# mc200 register map
Registers are 32-bit, access not given, no defined reset value unless marked. A register's access mark holds for its fields unless they carry their own. Addresses are absolute; registers are grouped by the start of their names; [hi:lo] are bit positions; {n}, {i} and the like mark numbered series; 'fields as' and 'values as' point back to an identical list.

## ACOMP
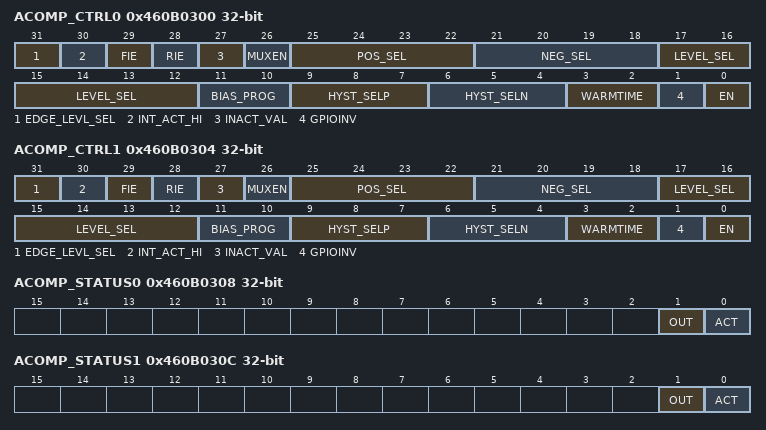
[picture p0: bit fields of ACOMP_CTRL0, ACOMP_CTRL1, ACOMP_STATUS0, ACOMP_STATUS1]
0x460B0300 ACOMP_CTRL0
  [31] EDGE_LEVL_SEL, [30] INT_ACT_HI, [29] FIE, [28] RIE, [27] INACT_VAL, [26] MUXEN, [25:22] POS_SEL, [21:18] NEG_SEL, [17:12] LEVEL_SEL, [11:10] BIAS_PROG, [9:7] HYST_SELP, [6:4] HYST_SELN, [3:2] WARMTIME, [1] GPIOINV, [0] EN
0x460B0304 ACOMP_CTRL1
  fields as ACOMP_CTRL0
0x460B0308 ACOMP_STATUS0
  [1] OUT, [0] ACT
0x460B030C ACOMP_STATUS1
  [1] OUT, [0] ACT
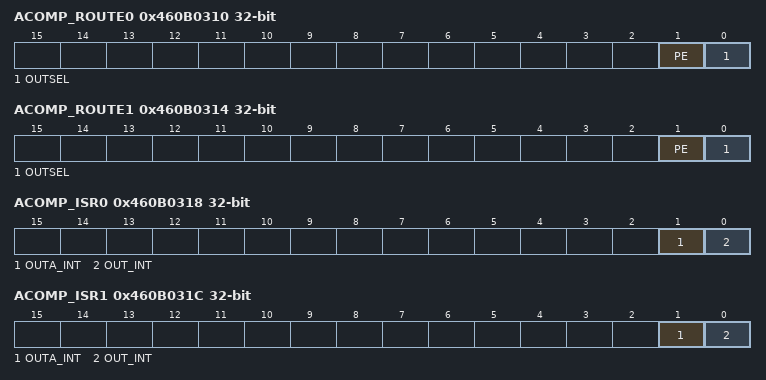
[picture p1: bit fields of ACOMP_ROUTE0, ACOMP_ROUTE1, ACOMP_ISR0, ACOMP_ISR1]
0x460B0310 ACOMP_ROUTE0
  [1] PE, [0] OUTSEL
0x460B0314 ACOMP_ROUTE1
  [1] PE, [0] OUTSEL
0x460B0318 ACOMP_ISR0
  [1] OUTA_INT, [0] OUT_INT
0x460B031C ACOMP_ISR1
  [1] OUTA_INT, [0] OUT_INT
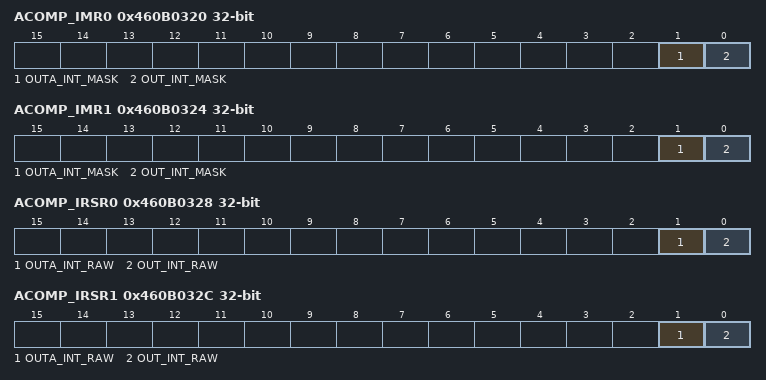
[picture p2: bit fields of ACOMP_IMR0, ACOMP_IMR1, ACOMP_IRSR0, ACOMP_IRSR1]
0x460B0320 ACOMP_IMR0
  [1] OUTA_INT_MASK, [0] OUT_INT_MASK
0x460B0324 ACOMP_IMR1
  [1] OUTA_INT_MASK, [0] OUT_INT_MASK
0x460B0328 ACOMP_IRSR0
  [1] OUTA_INT_RAW, [0] OUT_INT_RAW
0x460B032C ACOMP_IRSR1
  [1] OUTA_INT_RAW, [0] OUT_INT_RAW
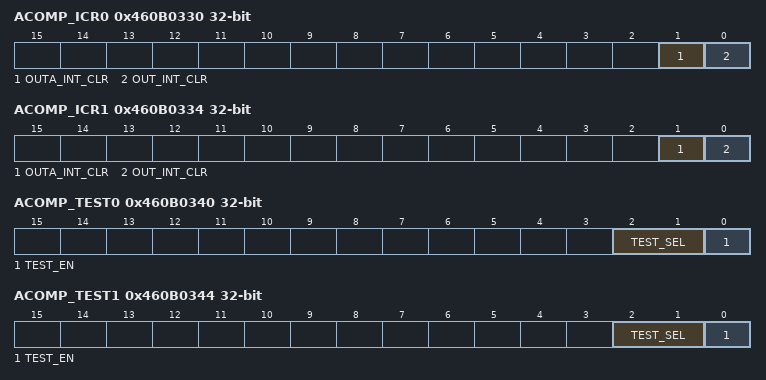
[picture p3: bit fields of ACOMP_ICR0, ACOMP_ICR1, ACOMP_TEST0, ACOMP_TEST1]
0x460B0330 ACOMP_ICR0
  [1] OUTA_INT_CLR, [0] OUT_INT_CLR
0x460B0334 ACOMP_ICR1
  [1] OUTA_INT_CLR, [0] OUT_INT_CLR
0x460B0338 ACOMP_RST0
  [0] SOFT_RST
0x460B033C ACOMP_RST1
  [0] SOFT_RST
0x460B0340 ACOMP_TEST0
  [2:1] TEST_SEL, [0] TEST_EN
0x460B0344 ACOMP_TEST1
  [2:1] TEST_SEL, [0] TEST_EN
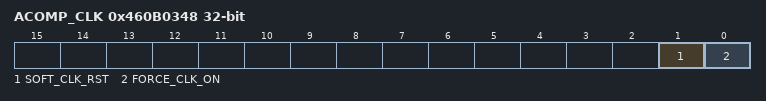
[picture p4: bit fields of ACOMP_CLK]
0x460B0348 ACOMP_CLK
  [1] SOFT_CLK_RST, [0] FORCE_CLK_ON
0x460B034C ACOMP_RSVD

## BG
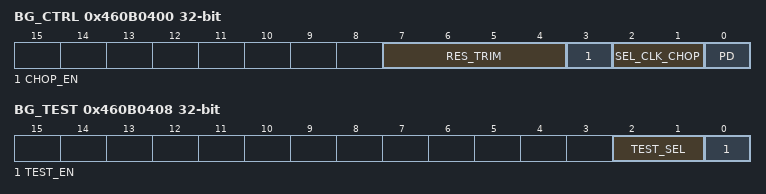
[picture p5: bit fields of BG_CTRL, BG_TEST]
0x460B0400 BG_CTRL
  [7:4] RES_TRIM, [3] CHOP_EN, [2:1] SEL_CLK_CHOP, [0] PD
0x460B0404 BG_STATUS
  [0] RDY
0x460B0408 BG_TEST
  [2:1] TEST_SEL, [0] TEST_EN
0x460B040C BG_RSVD

## CAUDBG
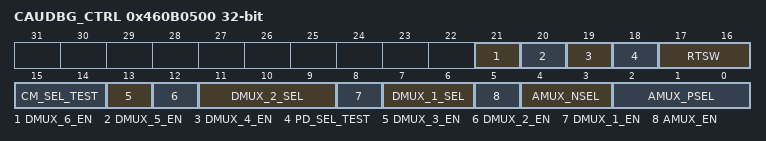
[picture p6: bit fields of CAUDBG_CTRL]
0x460B0500 CAUDBG_CTRL
  [21] DMUX_6_EN, [20] DMUX_5_EN, [19] DMUX_4_EN, [18] PD_SEL_TEST, [17:16] RTSW, [15:14] CM_SEL_TEST, [13] DMUX_3_EN, [12] DMUX_2_EN, [11:9] DMUX_2_SEL, [8] DMUX_1_EN, [7:6] DMUX_1_SEL, [5] AMUX_EN, [4:3] AMUX_NSEL, [2:0] AMUX_PSEL
0x460B0504 CAUDBG_RSVD

## SSP2
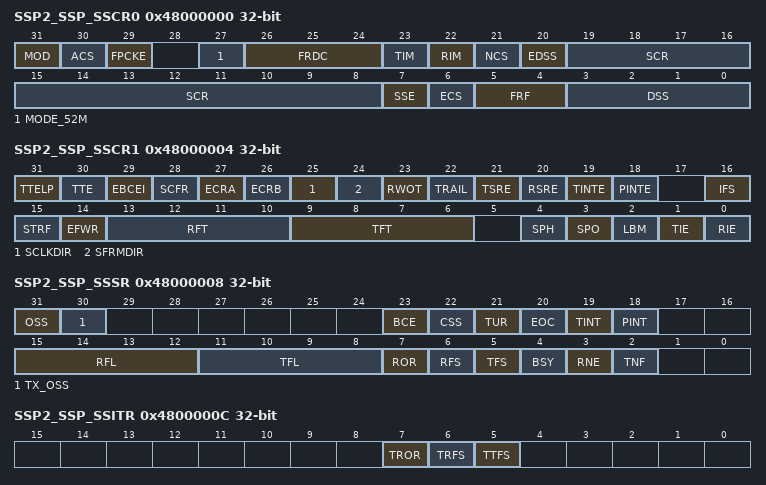
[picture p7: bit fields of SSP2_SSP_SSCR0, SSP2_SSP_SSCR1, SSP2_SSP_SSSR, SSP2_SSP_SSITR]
0x48000000 SSP2_SSP_SSCR0
  [31] MOD, [30] ACS, [29] FPCKE, [27] MODE_52M, [26:24] FRDC, [23] TIM, [22] RIM, [21] NCS, [20] EDSS, [19:8] SCR, [7] SSE, [6] ECS, [5:4] FRF, [3:0] DSS
0x48000004 SSP2_SSP_SSCR1
  [31] TTELP, [30] TTE, [29] EBCEI, [28] SCFR, [27] ECRA, [26] ECRB, [25] SCLKDIR, [24] SFRMDIR, [23] RWOT, [22] TRAIL, [21] TSRE, [20] RSRE, [19] TINTE, [18] PINTE, [16] IFS, [15] STRF, [14] EFWR, [13:10] RFT, [9:6] TFT, [4] SPH, [3] SPO, [2] LBM, [1] TIE, [0] RIE
0x48000008 SSP2_SSP_SSSR
  [31] OSS, [30] TX_OSS, [23] BCE, [22] CSS, [21] TUR, [20] EOC, [19] TINT, [18] PINT, [15:12] RFL, [11:8] TFL, [7] ROR, [6] RFS, [5] TFS, [4] BSY, [3] RNE, [2] TNF
0x4800000C SSP2_SSP_SSITR
  [7] TROR, [6] TRFS, [5] TTFS
0x48000010 SSP2_SSP_SSDR
  [31:0] DATA
0x48000028 SSP2_SSP_SSTO
  [23:0] TIMEOUT
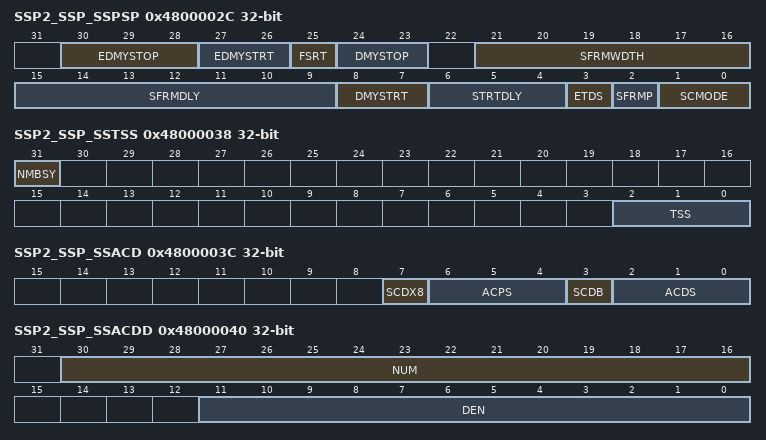
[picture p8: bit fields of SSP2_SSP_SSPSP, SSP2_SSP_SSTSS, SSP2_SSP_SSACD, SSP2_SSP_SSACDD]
0x4800002C SSP2_SSP_SSPSP
  [30:28] EDMYSTOP, [27:26] EDMYSTRT, [25] FSRT, [24:23] DMYSTOP, [21:16] SFRMWDTH, [15:9] SFRMDLY, [8:7] DMYSTRT, [6:4] STRTDLY, [3] ETDS, [2] SFRMP, [1:0] SCMODE
0x48000030 SSP2_SSP_SSTSA
  [7:0] TTSA
0x48000034 SSP2_SSP_SSRSA
  [7:0] RTSA
0x48000038 SSP2_SSP_SSTSS
  [31] NMBSY, [2:0] TSS
0x4800003C SSP2_SSP_SSACD
  [7] SCDX8, [6:4] ACPS, [3] SCDB, [2:0] ACDS
0x48000040 SSP2_SSP_SSACDD
  [30:16] NUM, [11:0] DEN

## PIN
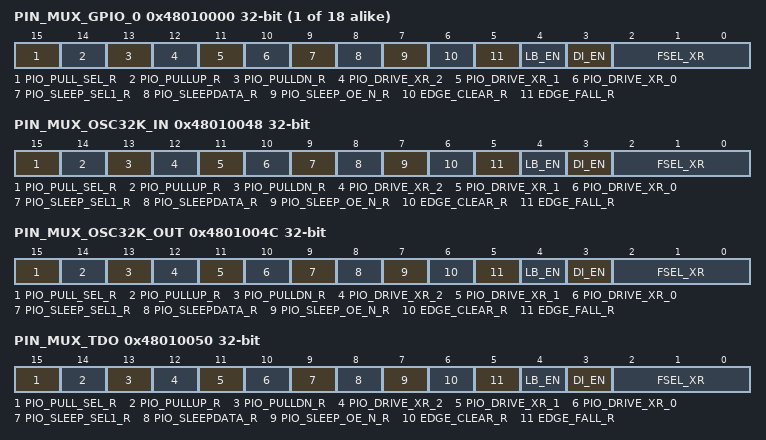
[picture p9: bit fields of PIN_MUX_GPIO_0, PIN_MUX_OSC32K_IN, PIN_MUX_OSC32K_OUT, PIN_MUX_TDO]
{0x48010000+4i} PIN_MUX_GPIO_{i} (i=0..17)
  [15] PIO_PULL_SEL_R, [14] PIO_PULLUP_R, [13] PIO_PULLDN_R, [12] PIO_DRIVE_XR_2, [11] PIO_DRIVE_XR_1, [10] PIO_DRIVE_XR_0, [9] PIO_SLEEP_SEL1_R, [8] PIO_SLEEPDATA_R, [7] PIO_SLEEP_OE_N_R, [6] EDGE_CLEAR_R, [5] EDGE_FALL_R, [4] LB_EN, [3] DI_EN, [2:0] FSEL_XR
0x48010048 PIN_MUX_OSC32K_IN
  fields as PIN_MUX_GPIO_0
0x4801004C PIN_MUX_OSC32K_OUT
  fields as PIN_MUX_GPIO_0
0x48010050 PIN_MUX_TDO
  fields as PIN_MUX_GPIO_0
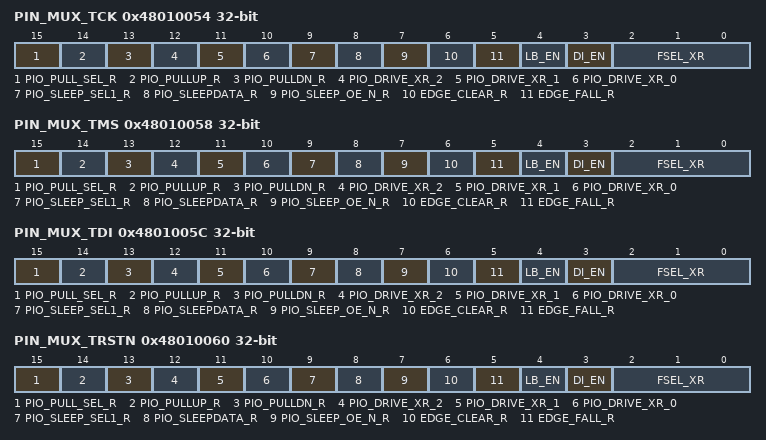
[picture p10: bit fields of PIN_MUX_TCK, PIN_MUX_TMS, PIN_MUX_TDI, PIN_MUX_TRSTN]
0x48010054 PIN_MUX_TCK
  fields as PIN_MUX_GPIO_0
0x48010058 PIN_MUX_TMS
  fields as PIN_MUX_GPIO_0
0x4801005C PIN_MUX_TDI
  fields as PIN_MUX_GPIO_0
0x48010060 PIN_MUX_TRSTN
  fields as PIN_MUX_GPIO_0
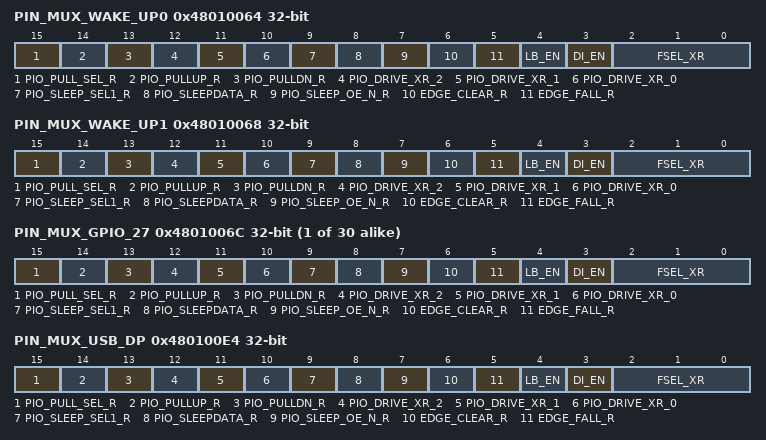
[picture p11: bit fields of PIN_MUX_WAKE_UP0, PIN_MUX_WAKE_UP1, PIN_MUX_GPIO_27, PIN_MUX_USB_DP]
0x48010064 PIN_MUX_WAKE_UP0
  fields as PIN_MUX_GPIO_0
0x48010068 PIN_MUX_WAKE_UP1
  fields as PIN_MUX_GPIO_0
{0x48010000+4i} PIN_MUX_GPIO_{i} (i=27..56)
  fields as PIN_MUX_GPIO_0
0x480100E4 PIN_MUX_USB_DP
  fields as PIN_MUX_GPIO_0
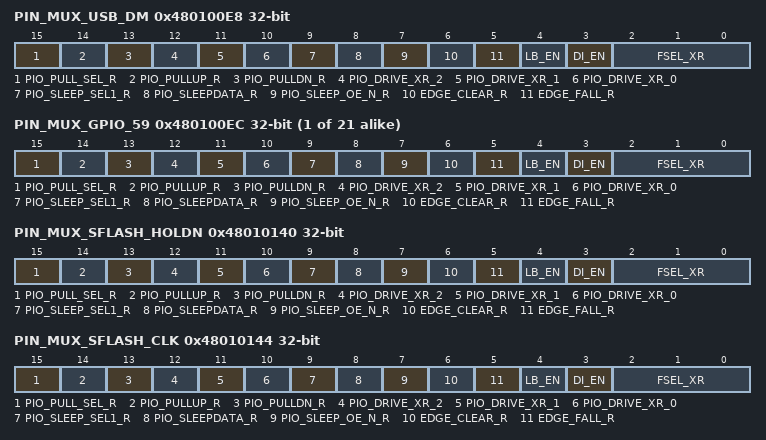
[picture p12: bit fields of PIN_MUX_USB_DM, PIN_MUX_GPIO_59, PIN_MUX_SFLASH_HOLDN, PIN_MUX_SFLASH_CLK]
0x480100E8 PIN_MUX_USB_DM
  fields as PIN_MUX_GPIO_0
{0x48010000+4i} PIN_MUX_GPIO_{i} (i=59..79)
  fields as PIN_MUX_GPIO_0
0x48010140 PIN_MUX_SFLASH_HOLDN
  fields as PIN_MUX_GPIO_0
0x48010144 PIN_MUX_SFLASH_CLK
  fields as PIN_MUX_GPIO_0
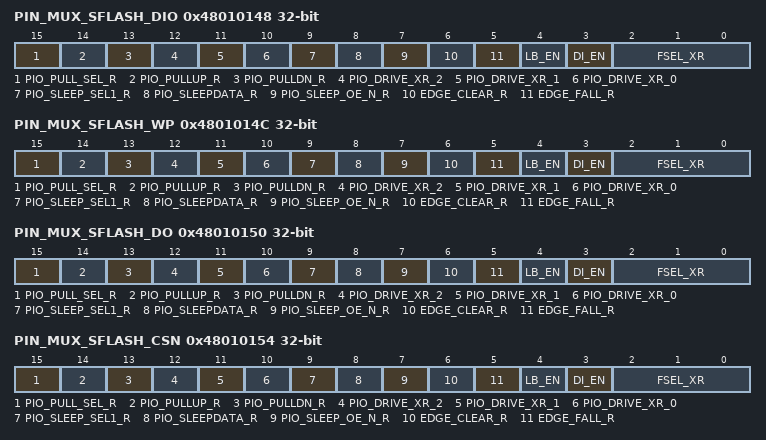
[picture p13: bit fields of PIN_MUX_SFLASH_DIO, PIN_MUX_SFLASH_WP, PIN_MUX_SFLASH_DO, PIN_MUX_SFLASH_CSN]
0x48010148 PIN_MUX_SFLASH_DIO
  fields as PIN_MUX_GPIO_0
0x4801014C PIN_MUX_SFLASH_WP
  fields as PIN_MUX_GPIO_0
0x48010150 PIN_MUX_SFLASH_DO
  fields as PIN_MUX_GPIO_0
0x48010154 PIN_MUX_SFLASH_CSN
  fields as PIN_MUX_GPIO_0
